VERSION "J35_6MT"

NS_ :

BS_:

BU_: PCM UNKNOWN

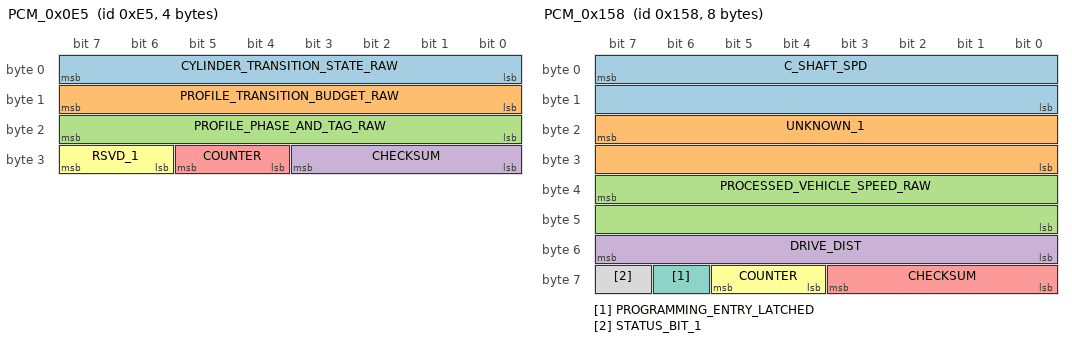
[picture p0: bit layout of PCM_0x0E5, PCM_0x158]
BO_ 229 PCM_0x0E5: 4 PCM
 SG_ CYLINDER_TRANSITION_STATE_RAW : 0|8@1+ (1,0) [0|255] ""  UNKNOWN
 SG_ PROFILE_TRANSITION_BUDGET_RAW : 8|8@1+ (1,0) [0|255] ""  UNKNOWN
 SG_ PROFILE_PHASE_AND_TAG_RAW : 16|8@1+ (1,0) [0|255] ""  UNKNOWN
 SG_ CHECKSUM : 24|4@1+ (1,0) [0|15] ""  UNKNOWN
 SG_ COUNTER : 28|2@1+ (1,0) [0|3] ""  UNKNOWN
 SG_ RSVD_1 : 30|2@1+ (1,0) [0|3] ""  UNKNOWN

BO_ 316 PCM_0x13C: 8 PCM
 SG_ TORQUE_ESTIMATE : 7|16@0- (1,0) [-32768|32767] "raw"  UNKNOWN
 SG_ TORQUE_TARGET : 23|16@0- (1,0) [-32768|32767] "raw"  UNKNOWN
 SG_ APP_SENSOR : 32|8@1+ (0.39215686274509803,0) [0|100] "%"  UNKNOWN
 SG_ TORQUE_STATE : 40|2@1+ (1,0) [0|3] ""  UNKNOWN
 SG_ RSVD_1 : 42|2@1+ (1,0) [0|3] ""  UNKNOWN
 SG_ RSVD_2 : 44|1@1+ (1,0) [0|1] ""  UNKNOWN
 SG_ FRAME_1AA_WINDOW_LATCH : 45|1@1+ (1,0) [0|1] ""  UNKNOWN
 SG_ START_PHASE_LATCH : 46|1@1+ (1,0) [0|1] ""  UNKNOWN
 SG_ DTC_STATUS_7_LATCH : 47|1@1+ (1,0) [0|1] ""  UNKNOWN
 SG_ RSVD_3 : 48|2@1+ (1,0) [0|3] ""  UNKNOWN
 SG_ CLUTCH_ENGAGEMENT_INFORMATION_CRUISE_CONTROL : 50|1@1+ (1,0) [0|1] ""  UNKNOWN
 SG_ CONTROL_GUARD_RAW : 51|1@1+ (1,0) [0|1] ""  UNKNOWN
 SG_ RSVD_4 : 52|4@1+ (1,0) [0|15] ""  UNKNOWN
 SG_ CHECKSUM : 56|4@1+ (1,0) [0|15] ""  UNKNOWN
 SG_ COUNTER : 60|2@1+ (1,0) [0|3] ""  UNKNOWN
 SG_ RSVD_5 : 62|1@1+ (1,0) [0|1] ""  UNKNOWN
 SG_ FRAME_1AA_INVALID_OR_FALLBACK_STATE_TBD : 63|1@1+ (1,0) [0|1] ""  UNKNOWN
VAL_ 316 CLUTCH_ENGAGEMENT_INFORMATION_CRUISE_CONTROL 0 "ON" 1 "OFF" ;
VAL_ 316 TORQUE_STATE 0 "NORMAL" 1 "VSA_CONTROL_CANDIDATE" 2 "FUEL_CUT" 3 "UNKNOWN" ;

BO_ 344 PCM_0x158: 8 PCM
 SG_ C_SHAFT_SPD : 7|16@0+ (0.01,0) [0|655.35] ""  UNKNOWN
 SG_ UNKNOWN_1 : 23|16@0+ (1,0) [0|65535] ""  UNKNOWN
 SG_ PROCESSED_VEHICLE_SPEED_RAW : 39|16@0+ (0.01,0) [0|655.35] ""  UNKNOWN
 SG_ DRIVE_DIST : 48|8@1+ (1,0) [0|255] "raw"  UNKNOWN
 SG_ CHECKSUM : 56|4@1+ (1,0) [0|15] ""  UNKNOWN
 SG_ COUNTER : 60|2@1+ (1,0) [0|3] ""  UNKNOWN
 SG_ PROGRAMMING_ENTRY_LATCHED : 62|1@1+ (1,0) [0|1] ""  UNKNOWN
 SG_ STATUS_BIT_1 : 63|1@1+ (1,0) [0|1] ""  UNKNOWN

BO_ 380 PCM_0x17C: 8 PCM
 SG_ APP_SENSOR : 0|8@1+ (0.39215686274509803,0) [0|100] "%"  UNKNOWN
 SG_ THROTTLE_ABOVE_IDLE_CODE : 8|8@1+ (0.4,0) [0|102] "deg"  UNKNOWN
 SG_ ENGINE_SPEED : 23|16@0+ (1,0) [0|65535] "rpm"  UNKNOWN
 SG_ BRAKE_SWITCH : 32|1@1+ (1,0) [0|1] ""  UNKNOWN
 SG_ CRUISE_CANCEL_EVENT : 33|1@1+ (1,0) [0|1] ""  UNKNOWN
 SG_ CRUISE_FAULT_SPEED_INHIBIT : 34|1@1+ (1,0) [0|1] ""  UNKNOWN
 SG_ CRUISE_ENGAGED : 35|1@1+ (1,0) [0|1] ""  UNKNOWN
 SG_ MIL : 36|1@1+ (1,0) [0|1] ""  UNKNOWN
 SG_ MIL_STATUS : 37|1@1+ (1,0) [0|1] ""  UNKNOWN
 SG_ CRUISE_INDICATOR : 38|1@1+ (1,0) [0|1] ""  UNKNOWN
 SG_ GAS_PEDAL_PRESSED : 39|1@1+ (1,0) [0|1] ""  UNKNOWN
 SG_ RSVD_1 : 40|2@1+ (1,0) [0|3] ""  UNKNOWN
 SG_ ACCEL_PEDAL_FAULT : 42|1@1+ (1,0) [0|1] ""  UNKNOWN
 SG_ RSVD_2 : 43|5@1+ (1,0) [0|31] ""  UNKNOWN
 SG_ RSVD_3 : 48|5@1+ (1,0) [0|31] ""  UNKNOWN
 SG_ CRUISE_BRAKE_SW_IDLE_STOP_SW : 53|1@1+ (1,0) [0|1] ""  UNKNOWN
 SG_ CRUISE_TRANS_REQUEST_WIRE : 54|2@1+ (1,0) [0|3] ""  UNKNOWN
 SG_ CHECKSUM : 56|4@1+ (1,0) [0|15] ""  UNKNOWN
 SG_ COUNTER : 60|2@1+ (1,0) [0|3] ""  UNKNOWN
 SG_ RSVD_4 : 62|1@1+ (1,0) [0|1] ""  UNKNOWN
 SG_ DTC_GROUP_WARNING_REQUESTED : 63|1@1+ (1,0) [0|1] ""  UNKNOWN
VAL_ 380 CRUISE_BRAKE_SW_IDLE_STOP_SW 0 "CLOSE" 1 "OPEN" ;
VAL_ 380 CRUISE_INDICATOR 0 "OFF" 1 "ON" ;
VAL_ 380 MIL_STATUS 0 "OFF" 1 "ON" ;
VAL_ 380 MIL 0 "OFF" 1 "ON" ;
VAL_ 380 BRAKE_SWITCH 0 "OFF" 1 "ON" ;

BO_ 392 PCM_0x188: 6 PCM
 SG_ SHIFT_CONTROL_CODE_A_RAW : 0|4@1+ (1,0) [0|15] ""  UNKNOWN
 SG_ TRANSMISSION_LATCH_RAW : 4|1@1+ (1,0) [0|1] ""  UNKNOWN
 SG_ CONDITIONED_GEAR_CODE_RAW : 5|3@1+ (1,0) [0|7] ""  UNKNOWN
 SG_ SHIFT_CONTROL_CODE_B_RAW : 8|3@1+ (1,0) [0|7] ""  UNKNOWN
 SG_ LED_C : 11|1@1+ (1,0) [0|1] ""  UNKNOWN
 SG_ LED_B : 12|1@1+ (1,0) [0|1] ""  UNKNOWN
 SG_ LED_A : 13|1@1+ (1,0) [0|1] ""  UNKNOWN
 SG_ SIGNED_CODE_SPILL_D1_RAW : 14|2@1+ (1,0) [0|3] ""  UNKNOWN
 SG_ SELECTOR_INDICATOR_RAW : 16|1@1+ (1,0) [0|1] ""  UNKNOWN
 SG_ TRANSMISSION_STATE_RAW : 17|1@1+ (1,0) [0|1] ""  UNKNOWN
 SG_ TRANSMISSION_QUALIFICATION_RAW : 18|1@1+ (1,0) [0|1] ""  UNKNOWN
 SG_ MANUAL_MODE_INDICATOR : 19|1@1+ (1,0) [0|1] ""  UNKNOWN
 SG_ INDICATOR_FAULT_RAW : 20|1@1+ (1,0) [0|1] ""  UNKNOWN
 SG_ TRANSMISSION_DIAGNOSTIC_LATCH_RAW : 21|1@1+ (1,0) [0|1] ""  UNKNOWN
 SG_ COMMUNICATION_STATUS_RAW : 22|1@1+ (1,0) [0|1] ""  UNKNOWN
 SG_ SHIFT_INDICATOR_CONTROL_RAW : 23|1@1+ (1,0) [0|1] ""  UNKNOWN
 SG_ A_T_P_SWITCH : 24|1@1+ (1,0) [0|1] ""  UNKNOWN
 SG_ A_T_R_SWITCH : 25|1@1+ (1,0) [0|1] ""  UNKNOWN
 SG_ A_T_N_SWITCH : 26|1@1+ (1,0) [0|1] ""  UNKNOWN
 SG_ A_T_D_SWITCH : 27|1@1+ (1,0) [0|1] ""  UNKNOWN
 SG_ RSVD_1 : 28|1@1+ (1,0) [0|1] ""  UNKNOWN
 SG_ A_T_D3_SWITCH : 29|1@1+ (1,0) [0|1] ""  UNKNOWN
 SG_ A_T_2_SWITCH_OR_A_T_L_SWITCH : 30|1@1+ (1,0) [0|1] ""  UNKNOWN
 SG_ A_T_1_SWITCH : 31|1@1+ (1,0) [0|1] ""  UNKNOWN
 SG_ SHIFT_POSITION_DISPLAY_CODE_RAW : 32|4@1+ (1,0) [0|15] ""  UNKNOWN
 SG_ A_T_S_SWITCH : 36|1@1+ (1,0) [0|1] ""  UNKNOWN
 SG_ SERVICE_RESET_ACK_RAW : 37|1@1+ (1,0) [0|1] ""  UNKNOWN
 SG_ SERVICE_DUE_RAW : 38|1@1+ (1,0) [0|1] ""  UNKNOWN
 SG_ SIGNED_CODE_SPILL_D4_RAW : 39|1@1+ (1,0) [0|1] ""  UNKNOWN
 SG_ CHECKSUM : 40|4@1+ (1,0) [0|15] ""  UNKNOWN
 SG_ COUNTER : 44|2@1+ (1,0) [0|3] ""  UNKNOWN
 SG_ QUALIFIED_TRANSMISSION_STATUS_RAW : 46|1@1+ (1,0) [0|1] ""  UNKNOWN
 SG_ RSVD_2 : 47|1@1+ (1,0) [0|1] ""  UNKNOWN
VAL_ 392 A_T_S_SWITCH 0 "OFF" 1 "ON" ;
VAL_ 392 A_T_1_SWITCH 0 "OFF" 1 "ON" ;
VAL_ 392 A_T_D3_SWITCH 0 "OFF" 1 "ON" ;
VAL_ 392 A_T_D_SWITCH 0 "OFF" 1 "ON" ;
VAL_ 392 A_T_N_SWITCH 0 "OFF" 1 "ON" ;
VAL_ 392 A_T_R_SWITCH 0 "OFF" 1 "ON" ;
VAL_ 392 A_T_P_SWITCH 0 "OFF" 1 "ON" ;
VAL_ 392 MANUAL_MODE_INDICATOR 0 "OFF" 1 "ON" ;
VAL_ 392 LED_A 0 "OFF" 1 "ON" ;
VAL_ 392 LED_B 0 "OFF" 1 "ON" ;
VAL_ 392 LED_C 0 "OFF" 1 "ON" ;

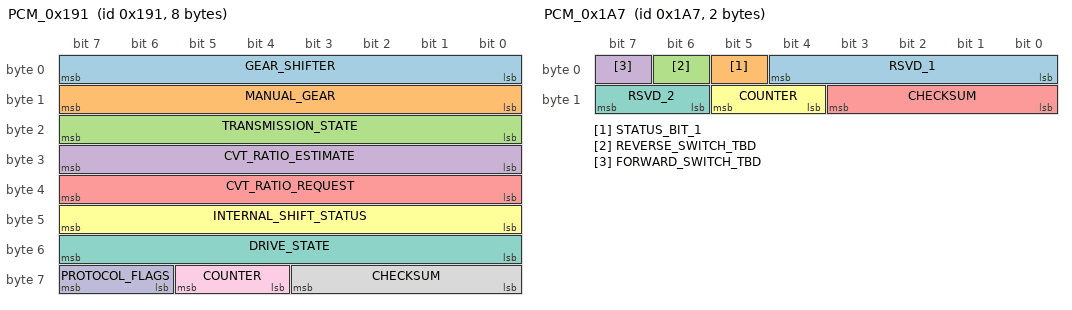
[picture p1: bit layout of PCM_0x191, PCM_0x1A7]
BO_ 401 PCM_0x191: 8 PCM
 SG_ GEAR_SHIFTER : 0|8@1+ (1,0) [0|255] ""  UNKNOWN
 SG_ MANUAL_GEAR : 8|8@1+ (1,0) [0|255] ""  UNKNOWN
 SG_ TRANSMISSION_STATE : 16|8@1+ (1,0) [0|255] ""  UNKNOWN
 SG_ CVT_RATIO_ESTIMATE : 24|8@1+ (1,0) [0|255] ""  UNKNOWN
 SG_ CVT_RATIO_REQUEST : 32|8@1+ (1,0) [0|255] ""  UNKNOWN
 SG_ INTERNAL_SHIFT_STATUS : 40|8@1+ (1,0) [0|255] ""  UNKNOWN
 SG_ DRIVE_STATE : 48|8@1+ (1,0) [0|255] ""  UNKNOWN
 SG_ CHECKSUM : 56|4@1+ (1,0) [0|15] ""  UNKNOWN
 SG_ COUNTER : 60|2@1+ (1,0) [0|3] ""  UNKNOWN
 SG_ PROTOCOL_FLAGS : 62|2@1+ (1,0) [0|3] ""  UNKNOWN

BO_ 423 PCM_0x1A7: 2 PCM
 SG_ RSVD_1 : 0|5@1+ (1,0) [0|31] ""  UNKNOWN
 SG_ STATUS_BIT_1 : 5|1@1+ (1,0) [0|1] ""  UNKNOWN
 SG_ REVERSE_SWITCH_TBD : 6|1@1+ (1,0) [0|1] ""  UNKNOWN
 SG_ FORWARD_SWITCH_TBD : 7|1@1+ (1,0) [0|1] ""  UNKNOWN
 SG_ CHECKSUM : 8|4@1+ (1,0) [0|15] ""  UNKNOWN
 SG_ COUNTER : 12|2@1+ (1,0) [0|3] ""  UNKNOWN
 SG_ RSVD_2 : 14|2@1+ (1,0) [0|3] ""  UNKNOWN

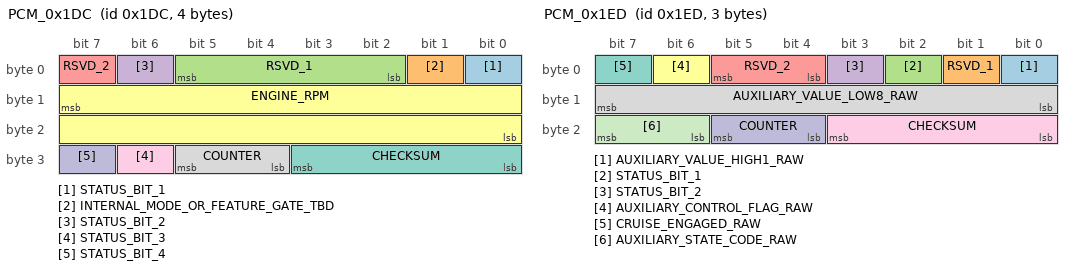
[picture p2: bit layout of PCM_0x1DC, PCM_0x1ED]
BO_ 476 PCM_0x1DC: 4 PCM
 SG_ STATUS_BIT_1 : 0|1@1+ (1,0) [0|1] ""  UNKNOWN
 SG_ INTERNAL_MODE_OR_FEATURE_GATE_TBD : 1|1@1+ (1,0) [0|1] ""  UNKNOWN
 SG_ RSVD_1 : 2|4@1+ (1,0) [0|15] ""  UNKNOWN
 SG_ STATUS_BIT_2 : 6|1@1+ (1,0) [0|1] ""  UNKNOWN
 SG_ RSVD_2 : 7|1@1+ (1,0) [0|1] ""  UNKNOWN
 SG_ ENGINE_RPM : 15|16@0+ (1,0) [0|65535] "rpm"  UNKNOWN
 SG_ CHECKSUM : 24|4@1+ (1,0) [0|15] ""  UNKNOWN
 SG_ COUNTER : 28|2@1+ (1,0) [0|3] ""  UNKNOWN
 SG_ STATUS_BIT_3 : 30|1@1+ (1,0) [0|1] ""  UNKNOWN
 SG_ STATUS_BIT_4 : 31|1@1+ (1,0) [0|1] ""  UNKNOWN

BO_ 493 PCM_0x1ED: 3 PCM
 SG_ AUXILIARY_VALUE_HIGH1_RAW : 0|1@1+ (1,0) [0|1] ""  UNKNOWN
 SG_ RSVD_1 : 1|1@1+ (1,0) [0|1] ""  UNKNOWN
 SG_ STATUS_BIT_1 : 2|1@1+ (1,0) [0|1] ""  UNKNOWN
 SG_ STATUS_BIT_2 : 3|1@1+ (1,0) [0|1] ""  UNKNOWN
 SG_ RSVD_2 : 4|2@1+ (1,0) [0|3] ""  UNKNOWN
 SG_ AUXILIARY_CONTROL_FLAG_RAW : 6|1@1+ (1,0) [0|1] ""  UNKNOWN
 SG_ CRUISE_ENGAGED_RAW : 7|1@1+ (1,0) [0|1] ""  UNKNOWN
 SG_ AUXILIARY_VALUE_LOW8_RAW : 8|8@1+ (1,0) [0|255] ""  UNKNOWN
 SG_ CHECKSUM : 16|4@1+ (1,0) [0|15] ""  UNKNOWN
 SG_ COUNTER : 20|2@1+ (1,0) [0|3] ""  UNKNOWN
 SG_ AUXILIARY_STATE_CODE_RAW : 22|2@1+ (1,0) [0|3] ""  UNKNOWN

BO_ 800 BCM_0x320: 8 PCM
 SG_ RSVD_1 : 0|6@1+ (1,0) [0|63] ""  UNKNOWN
 SG_ ENGINE_STATE_CODE_TBD : 6|2@1+ (1,0) [0|3] ""  UNKNOWN
 SG_ STATUS_BIT_1 : 8|1@1+ (1,0) [0|1] ""  UNKNOWN
 SG_ STATUS_BIT_2 : 9|1@1+ (1,0) [0|1] ""  UNKNOWN
 SG_ RSVD_2 : 10|4@1+ (1,0) [0|15] ""  UNKNOWN
 SG_ STATUS_BIT_3 : 14|1@1+ (1,0) [0|1] ""  UNKNOWN
 SG_ RSVD_3 : 15|1@1+ (1,0) [0|1] ""  UNKNOWN
 SG_ UNKNOWN_1 : 16|3@1+ (1,0) [0|7] ""  UNKNOWN
 SG_ SIGNED_CAP_OUT_OF_DOMAIN_HIGH_BITS_B2_TBD : 19|3@1+ (1,0) [0|7] ""  UNKNOWN
 SG_ STATUS_BIT_4 : 22|1@1+ (1,0) [0|1] ""  UNKNOWN
 SG_ SIGNED_CAP_OUT_OF_DOMAIN_SIGN_BIT_B2_TBD : 23|1@1+ (1,0) [0|1] ""  UNKNOWN
 SG_ RSVD_4 : 24|8@1+ (1,0) [0|255] ""  UNKNOWN
 SG_ RSVD_5 : 32|7@1+ (1,0) [0|127] ""  UNKNOWN
 SG_ STATUS_BIT_5 : 39|1@1+ (1,0) [0|1] ""  UNKNOWN
 SG_ UNKNOWN_2 : 40|3@1+ (1,0) [0|7] ""  UNKNOWN
 SG_ UNKNOWN_3 : 43|3@1+ (1,0) [0|7] ""  UNKNOWN
 SG_ SIGNED_CAP_OUT_OF_DOMAIN_HIGH_BITS_B5_TBD : 46|2@1+ (1,0) [0|3] ""  UNKNOWN
 SG_ STATUS_BIT_6 : 48|1@1+ (1,0) [0|1] ""  UNKNOWN
 SG_ RSVD_6 : 49|2@1+ (1,0) [0|3] ""  UNKNOWN
 SG_ STATUS_BIT_7 : 51|1@1+ (1,0) [0|1] ""  UNKNOWN
 SG_ RSVD_7 : 52|4@1+ (1,0) [0|15] ""  UNKNOWN
 SG_ CHECKSUM : 56|4@1+ (1,0) [0|15] ""  UNKNOWN
 SG_ COUNTER : 60|2@1+ (1,0) [0|3] ""  UNKNOWN
 SG_ STATUS_BIT_8 : 62|1@1+ (1,0) [0|1] ""  UNKNOWN
 SG_ STATUS_BIT_9 : 63|1@1+ (1,0) [0|1] ""  UNKNOWN

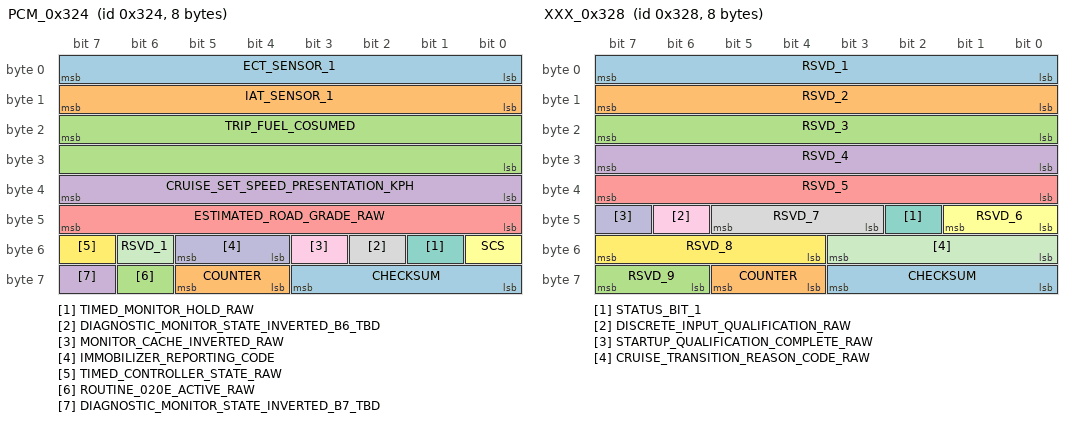
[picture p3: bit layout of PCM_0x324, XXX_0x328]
BO_ 804 PCM_0x324: 8 PCM
 SG_ ECT_SENSOR_1 : 0|8@1+ (1,-40) [-40|215] "degC"  UNKNOWN
 SG_ IAT_SENSOR_1 : 8|8@1+ (1,-40) [-40|215] "degC"  UNKNOWN
 SG_ TRIP_FUEL_COSUMED : 23|16@0+ (1,0) [0|65535] ""  UNKNOWN
 SG_ CRUISE_SET_SPEED_PRESENTATION_KPH : 32|8@1+ (1,0) [0|255] "raw"  UNKNOWN
 SG_ ESTIMATED_ROAD_GRADE_RAW : 40|8@1- (0.125,0) [-16|15.875] ""  UNKNOWN
 SG_ SCS : 48|1@1+ (1,0) [0|1] ""  UNKNOWN
 SG_ TIMED_MONITOR_HOLD_RAW : 49|1@1+ (1,0) [0|1] ""  UNKNOWN
 SG_ DIAGNOSTIC_MONITOR_STATE_INVERTED_B6_TBD : 50|1@1+ (1,0) [0|1] ""  UNKNOWN
 SG_ MONITOR_CACHE_INVERTED_RAW : 51|1@1+ (1,0) [0|1] ""  UNKNOWN
 SG_ IMMOBILIZER_REPORTING_CODE : 52|2@1+ (1,0) [0|3] ""  UNKNOWN
 SG_ RSVD_1 : 54|1@1+ (1,0) [0|1] ""  UNKNOWN
 SG_ TIMED_CONTROLLER_STATE_RAW : 55|1@1+ (1,0) [0|1] ""  UNKNOWN
 SG_ CHECKSUM : 56|4@1+ (1,0) [0|15] ""  UNKNOWN
 SG_ COUNTER : 60|2@1+ (1,0) [0|3] ""  UNKNOWN
 SG_ ROUTINE_020E_ACTIVE_RAW : 62|1@1+ (1,0) [0|1] ""  UNKNOWN
 SG_ DIAGNOSTIC_MONITOR_STATE_INVERTED_B7_TBD : 63|1@1+ (1,0) [0|1] ""  UNKNOWN
VAL_ 804 IMMOBILIZER_REPORTING_CODE 0 "COMPLETE_ACCEPTED" 1 "INCOMPLETE" 2 "COMPLETE_NOT_ACCEPTED" ;
VAL_ 804 SCS 0 "OPEN" 1 "SHORT" ;
VAL_ 804 IAT_SENSOR_1 255 "INVALID" ;
VAL_ 804 ECT_SENSOR_1 255 "INVALID" ;

BO_ 808 XXX_0x328: 8 PCM
 SG_ RSVD_1 : 0|8@1+ (1,0) [0|255] ""  UNKNOWN
 SG_ RSVD_2 : 8|8@1+ (1,0) [0|255] ""  UNKNOWN
 SG_ RSVD_3 : 16|8@1+ (1,0) [0|255] ""  UNKNOWN
 SG_ RSVD_4 : 24|8@1+ (1,0) [0|255] ""  UNKNOWN
 SG_ RSVD_5 : 32|8@1+ (1,0) [0|255] ""  UNKNOWN
 SG_ RSVD_6 : 40|2@1+ (1,0) [0|3] ""  UNKNOWN
 SG_ STATUS_BIT_1 : 42|1@1+ (1,0) [0|1] ""  UNKNOWN
 SG_ RSVD_7 : 43|3@1+ (1,0) [0|7] ""  UNKNOWN
 SG_ DISCRETE_INPUT_QUALIFICATION_RAW : 46|1@1+ (1,0) [0|1] ""  UNKNOWN
 SG_ STARTUP_QUALIFICATION_COMPLETE_RAW : 47|1@1+ (1,0) [0|1] ""  UNKNOWN
 SG_ CRUISE_TRANSITION_REASON_CODE_RAW : 48|4@1+ (1,0) [0|15] ""  UNKNOWN
 SG_ RSVD_8 : 52|4@1+ (1,0) [0|15] ""  UNKNOWN
 SG_ CHECKSUM : 56|4@1+ (1,0) [0|15] ""  UNKNOWN
 SG_ COUNTER : 60|2@1+ (1,0) [0|3] ""  UNKNOWN
 SG_ RSVD_9 : 62|2@1+ (1,0) [0|3] ""  UNKNOWN

BO_ 892 PCM_0x37C: 8 PCM
 SG_ UNKNOWN_1 : 0|8@1+ (1,0) [0|255] ""  UNKNOWN
 SG_ UNKNOWN_2 : 8|8@1+ (1,0) [0|255] ""  UNKNOWN
 SG_ UNKNOWN_3 : 16|8@1+ (1,0) [0|255] ""  UNKNOWN
 SG_ UNKNOWN_4 : 24|8@1+ (1,0) [0|255] ""  UNKNOWN
 SG_ RSVD_1 : 32|8@1+ (1,0) [0|255] ""  UNKNOWN
 SG_ UNKNOWN_5 : 40|7@1+ (1,0) [0|127] ""  UNKNOWN
 SG_ STATUS_BIT_1 : 47|1@1+ (1,0) [0|1] ""  UNKNOWN
 SG_ STATUS_BIT_2 : 48|1@1+ (1,0) [0|1] ""  UNKNOWN
 SG_ STATUS_BIT_3 : 49|1@1+ (1,0) [0|1] ""  UNKNOWN
 SG_ STATUS_BIT_4 : 50|1@1+ (1,0) [0|1] ""  UNKNOWN
 SG_ STATUS_BIT_5 : 51|1@1+ (1,0) [0|1] ""  UNKNOWN
 SG_ STATUS_BIT_6 : 52|1@1+ (1,0) [0|1] ""  UNKNOWN
 SG_ STATUS_BIT_7 : 53|1@1+ (1,0) [0|1] ""  UNKNOWN
 SG_ STATUS_BIT_8 : 54|1@1+ (1,0) [0|1] ""  UNKNOWN
 SG_ STATUS_BIT_9 : 55|1@1+ (1,0) [0|1] ""  UNKNOWN
 SG_ CHECKSUM : 56|4@1+ (1,0) [0|15] ""  UNKNOWN
 SG_ COUNTER : 60|2@1+ (1,0) [0|3] ""  UNKNOWN
 SG_ RSVD_2 : 62|1@1+ (1,0) [0|1] ""  UNKNOWN
 SG_ STATUS_BIT_10 : 63|1@1+ (1,0) [0|1] ""  UNKNOWN

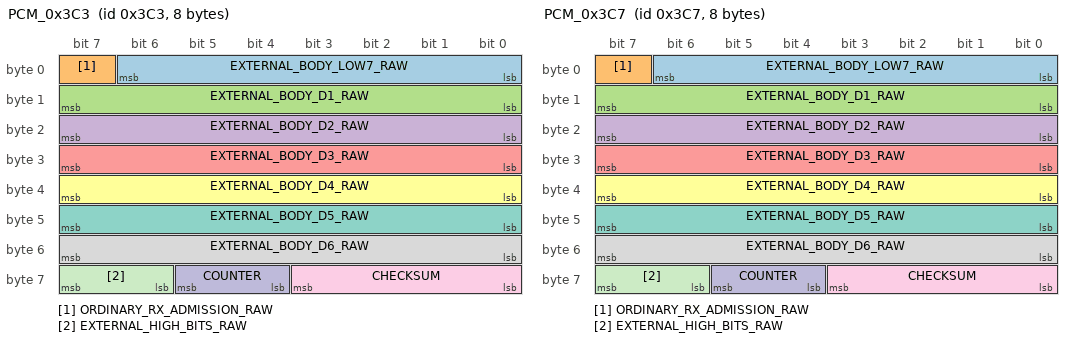
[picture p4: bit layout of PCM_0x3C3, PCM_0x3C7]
BO_ 963 PCM_0x3C3: 8 PCM
 SG_ EXTERNAL_BODY_LOW7_RAW : 0|7@1+ (1,0) [0|0] ""  UNKNOWN
 SG_ ORDINARY_RX_ADMISSION_RAW : 7|1@1+ (1,0) [0|0] ""  UNKNOWN
 SG_ EXTERNAL_BODY_D1_RAW : 8|8@1+ (1,0) [0|0] ""  UNKNOWN
 SG_ EXTERNAL_BODY_D2_RAW : 16|8@1+ (1,0) [0|0] ""  UNKNOWN
 SG_ EXTERNAL_BODY_D3_RAW : 24|8@1+ (1,0) [0|0] ""  UNKNOWN
 SG_ EXTERNAL_BODY_D4_RAW : 32|8@1+ (1,0) [0|0] ""  UNKNOWN
 SG_ EXTERNAL_BODY_D5_RAW : 40|8@1+ (1,0) [0|0] ""  UNKNOWN
 SG_ EXTERNAL_BODY_D6_RAW : 48|8@1+ (1,0) [0|0] ""  UNKNOWN
 SG_ CHECKSUM : 56|4@1+ (1,0) [0|0] ""  UNKNOWN
 SG_ COUNTER : 60|2@1+ (1,0) [0|0] ""  UNKNOWN
 SG_ EXTERNAL_HIGH_BITS_RAW : 62|2@1+ (1,0) [0|0] ""  UNKNOWN

BO_ 967 PCM_0x3C7: 8 PCM
 SG_ EXTERNAL_BODY_LOW7_RAW : 0|7@1+ (1,0) [0|0] ""  UNKNOWN
 SG_ ORDINARY_RX_ADMISSION_RAW : 7|1@1+ (1,0) [0|0] ""  UNKNOWN
 SG_ EXTERNAL_BODY_D1_RAW : 8|8@1+ (1,0) [0|0] ""  UNKNOWN
 SG_ EXTERNAL_BODY_D2_RAW : 16|8@1+ (1,0) [0|0] ""  UNKNOWN
 SG_ EXTERNAL_BODY_D3_RAW : 24|8@1+ (1,0) [0|0] ""  UNKNOWN
 SG_ EXTERNAL_BODY_D4_RAW : 32|8@1+ (1,0) [0|0] ""  UNKNOWN
 SG_ EXTERNAL_BODY_D5_RAW : 40|8@1+ (1,0) [0|0] ""  UNKNOWN
 SG_ EXTERNAL_BODY_D6_RAW : 48|8@1+ (1,0) [0|0] ""  UNKNOWN
 SG_ CHECKSUM : 56|4@1+ (1,0) [0|0] ""  UNKNOWN
 SG_ COUNTER : 60|2@1+ (1,0) [0|0] ""  UNKNOWN
 SG_ EXTERNAL_HIGH_BITS_RAW : 62|2@1+ (1,0) [0|0] ""  UNKNOWN

BO_ 983 PCM_0x3D7: 8 PCM
 SG_ MULTIPLEX_HEADER : 0|8@1+ (1,0) [0|255] ""  UNKNOWN
 SG_ RETAINED_BANK_A_CODE_WORD_0_PAGE_0 m0 : 15|16@0+ (1,0) [0|65535] ""  UNKNOWN
 SG_ RETAINED_BANK_A_CODE_WORD_0_PAGE_1 m1 : 15|16@0+ (1,0) [0|65535] ""  UNKNOWN
 SG_ RETAINED_BANK_A_CODE_WORD_1_PAGE_0 m0 : 31|16@0+ (1,0) [0|65535] ""  UNKNOWN
 SG_ RETAINED_BANK_A_CODE_WORD_1_PAGE_1 m1 : 31|16@0+ (1,0) [0|65535] ""  UNKNOWN
 SG_ RETAINED_BANK_A_CODE_WORD_2_PAGE_0 m0 : 47|16@0+ (1,0) [0|65535] ""  UNKNOWN
 SG_ RETAINED_BANK_A_CODE_WORD_2_PAGE_1 m1 : 47|16@0+ (1,0) [0|65535] ""  UNKNOWN
 SG_ CHECKSUM : 56|4@1+ (1,0) [0|15] ""  UNKNOWN
 SG_ COUNTER : 60|2@1+ (1,0) [0|3] ""  UNKNOWN
 SG_ PAGE_INDEX M : 62|1@1+ (1,0) [0|1] ""  UNKNOWN
 SG_ PROTOCOL_BIT7 : 63|1@1+ (1,0) [0|1] ""  UNKNOWN
VAL_ 983 PAGE_INDEX 0 "SLOTS0_TO2" 1 "SLOTS3_TO5" ;
SG_MUL_VAL_ 983 RETAINED_BANK_A_CODE_WORD_0_PAGE_0 PAGE_INDEX 0-0;
SG_MUL_VAL_ 983 RETAINED_BANK_A_CODE_WORD_0_PAGE_1 PAGE_INDEX 1-1;
SG_MUL_VAL_ 983 RETAINED_BANK_A_CODE_WORD_1_PAGE_0 PAGE_INDEX 0-0;
SG_MUL_VAL_ 983 RETAINED_BANK_A_CODE_WORD_1_PAGE_1 PAGE_INDEX 1-1;
SG_MUL_VAL_ 983 RETAINED_BANK_A_CODE_WORD_2_PAGE_0 PAGE_INDEX 0-0;
SG_MUL_VAL_ 983 RETAINED_BANK_A_CODE_WORD_2_PAGE_1 PAGE_INDEX 1-1;

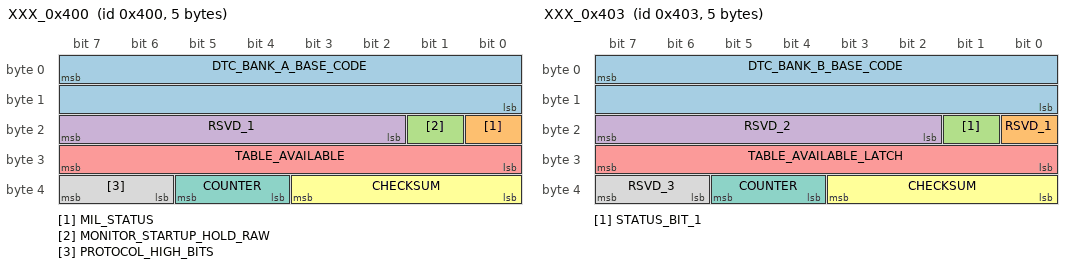
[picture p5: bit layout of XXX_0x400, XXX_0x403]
BO_ 1024 XXX_0x400: 5 PCM
 SG_ DTC_BANK_A_BASE_CODE : 7|16@0+ (1,0) [0|65535] ""  UNKNOWN
 SG_ MIL_STATUS : 16|1@1+ (1,0) [0|1] ""  UNKNOWN
 SG_ MONITOR_STARTUP_HOLD_RAW : 17|1@1+ (1,0) [0|1] ""  UNKNOWN
 SG_ RSVD_1 : 18|6@1+ (1,0) [0|63] ""  UNKNOWN
 SG_ TABLE_AVAILABLE : 24|8@1+ (1,0) [0|255] ""  UNKNOWN
 SG_ CHECKSUM : 32|4@1+ (1,0) [0|15] ""  UNKNOWN
 SG_ COUNTER : 36|2@1+ (1,0) [0|3] ""  UNKNOWN
 SG_ PROTOCOL_HIGH_BITS : 38|2@1+ (1,0) [0|3] ""  UNKNOWN
VAL_ 1024 MIL_STATUS 0 "OFF" 1 "ON" ;

BO_ 1027 XXX_0x403: 5 PCM
 SG_ DTC_BANK_B_BASE_CODE : 7|16@0+ (1,0) [0|65535] ""  UNKNOWN
 SG_ RSVD_1 : 16|1@1+ (1,0) [0|1] ""  UNKNOWN
 SG_ STATUS_BIT_1 : 17|1@1+ (1,0) [0|1] ""  UNKNOWN
 SG_ RSVD_2 : 18|6@1+ (1,0) [0|63] ""  UNKNOWN
 SG_ TABLE_AVAILABLE_LATCH : 24|8@1+ (1,0) [0|255] ""  UNKNOWN
 SG_ CHECKSUM : 32|4@1+ (1,0) [0|15] ""  UNKNOWN
 SG_ COUNTER : 36|2@1+ (1,0) [0|3] ""  UNKNOWN
 SG_ RSVD_3 : 38|2@1+ (1,0) [0|3] ""  UNKNOWN

BO_ 1036 XXX_0x40C: 8 PCM
 SG_ MULTIPLEX_PAGE M : 0|4@1+ (1,0) [0|15] ""  UNKNOWN
 SG_ MULTIPLEX_GROUP : 4|2@1+ (1,0) [0|3] ""  UNKNOWN
 SG_ DIAGNOSTIC_EVENT_STATE : 6|2@1+ (1,0) [0|3] ""  UNKNOWN
 SG_ UNKNOWN_1 m0 : 8|8@1+ (1,0) [0|255] ""  UNKNOWN
 SG_ UNKNOWN_2 m1 : 8|8@1+ (1,0) [0|255] ""  UNKNOWN
 SG_ UNKNOWN_3 m2 : 8|8@1+ (1,0) [0|255] ""  UNKNOWN
 SG_ UNKNOWN_4 m3 : 8|8@1+ (1,0) [0|255] ""  UNKNOWN
 SG_ UNKNOWN_5 m4 : 8|8@1+ (1,0) [0|255] ""  UNKNOWN
 SG_ P05_ENGINE_SPEED m5 : 15|16@0+ (0.25,0) [0|16383.75] "rpm"  UNKNOWN
 SG_ UNKNOWN_6 m6 : 8|8@1+ (0.0196078431372549,0) [0|5] "V"  UNKNOWN
 SG_ UNKNOWN_7 m7 : 8|8@1+ (1,0) [0|255] "km/h"  UNKNOWN
 SG_ UNKNOWN_8 m8 : 15|16@0+ (0.005,0) [0|327.675] "%"  UNKNOWN
 SG_ UNKNOWN_9 m9 : 15|16@0+ (0.005,0) [0|327.675] "deg"  UNKNOWN
 SG_ UNKNOWN_10 m10 : 15|16@0+ (1,0) [0|65535] ""  UNKNOWN
 SG_ UNKNOWN_11 m11 : 8|8@1+ (1,0) [0|255] ""  UNKNOWN
 SG_ UNKNOWN_12 m12 : 8|8@1+ (1,0) [0|255] ""  UNKNOWN
 SG_ UNKNOWN_13 m13 : 8|8@1+ (1,0) [0|255] ""  UNKNOWN
 SG_ UNKNOWN_14 m14 : 15|16@0+ (0.01,0) [0|655.35] "g/s"  UNKNOWN
 SG_ UNKNOWN_15 m15 : 8|8@1+ (0.39215686274509803,0) [0|100] "%"  UNKNOWN
 SG_ UNKNOWN_16 m0 : 23|16@0+ (1,0) [0|65535] ""  UNKNOWN
 SG_ UNKNOWN_17 m1 : 16|8@1+ (1,0) [0|255] ""  UNKNOWN
 SG_ UNKNOWN_18 m2 : 16|8@1+ (1,0) [0|255] ""  UNKNOWN
 SG_ UNKNOWN_19 m3 : 16|8@1+ (1,0) [0|255] ""  UNKNOWN
 SG_ UNKNOWN_20 m4 : 16|8@1+ (1,0) [0|255] ""  UNKNOWN
 SG_ UNKNOWN_21 m6 : 16|8@1+ (1,-40) [-40|215] "degC"  UNKNOWN
 SG_ UNKNOWN_22 m7 : 16|8@1+ (0.39215686274509803,0) [0|100] "%"  UNKNOWN
 SG_ UNKNOWN_23 m11 : 16|8@1+ (1,0) [0|255] ""  UNKNOWN
 SG_ UNKNOWN_24 m12 : 16|8@1+ (1,0) [0|255] ""  UNKNOWN
 SG_ UNKNOWN_25 m13 : 16|8@1+ (1,0) [0|255] ""  UNKNOWN
 SG_ UNKNOWN_26 m15 : 16|8@1+ (1,0) [0|255] ""  UNKNOWN
 SG_ UNKNOWN_27 m1 : 24|8@1+ (1,0) [0|255] ""  UNKNOWN
 SG_ UNKNOWN_28 m2 : 24|8@1+ (1,0) [0|255] ""  UNKNOWN
 SG_ UNKNOWN_29 m3 : 24|8@1+ (1,0) [0|255] ""  UNKNOWN
 SG_ UNKNOWN_30 m4 : 24|8@1+ (1,0) [0|255] ""  UNKNOWN
 SG_ UNKNOWN_31 m5 : 24|8@1+ (0.39215686274509803,0) [0|100] "%"  UNKNOWN
 SG_ UNKNOWN_32 m6 : 24|8@1+ (0.0196078431372549,0) [0|5] "V"  UNKNOWN
 SG_ UNKNOWN_33 m7 : 24|8@1+ (0.5,-64) [-64|63.5] "deg"  UNKNOWN
 SG_ UNKNOWN_34 m8 : 24|8@1+ (0.0196078431372549,0) [0|5] "V"  UNKNOWN
 SG_ UNKNOWN_35 m9 : 24|8@1+ (1,0) [0|255] ""  UNKNOWN
 SG_ UNKNOWN_36 m10 : 31|16@0+ (1,0) [0|65535] ""  UNKNOWN
 SG_ UNKNOWN_37 m11 : 31|16@0+ (1,0) [0|65535] ""  UNKNOWN
 SG_ UNKNOWN_38 m12 : 24|8@1+ (1,0) [0|255] ""  UNKNOWN
 SG_ UNKNOWN_39 m13 : 24|8@1+ (1,0) [0|255] ""  UNKNOWN
 SG_ UNKNOWN_40 m14 : 24|8@1+ (1,0) [0|255] ""  UNKNOWN
 SG_ UNKNOWN_41 m15 : 24|8@1+ (1,0) [0|255] ""  UNKNOWN
 SG_ UNKNOWN_42 m0 : 32|8@1+ (1,0) [0|255] ""  UNKNOWN
 SG_ UNKNOWN_43 m1 : 32|8@1+ (1,0) [0|255] ""  UNKNOWN
 SG_ UNKNOWN_44 m2 : 32|8@1+ (1,0) [0|255] ""  UNKNOWN
 SG_ UNKNOWN_45 m3 : 32|8@1+ (1,0) [0|255] ""  UNKNOWN
 SG_ UNKNOWN_46 m4 : 32|8@1+ (1,0) [0|255] ""  UNKNOWN
 SG_ UNKNOWN_47 m5 : 32|8@1+ (0.39215686274509803,0) [0|100] "%"  UNKNOWN
 SG_ UNKNOWN_48 m6 : 32|8@1+ (1,0) [0|255] "kPa"  UNKNOWN
 SG_ P07_CONTROL_MODULE_VOLTAGE_DECIVOLT_RAW m7 : 32|8@1+ (0.1,0) [0|25.5] "V"  UNKNOWN
 SG_ UNKNOWN_49 m8 : 32|8@1+ (0.0196078431372549,0) [0|5] "V"  UNKNOWN
 SG_ UNKNOWN_50 m9 : 32|8@1+ (1,0) [0|255] ""  UNKNOWN
 SG_ UNKNOWN_51 m12 : 32|8@1+ (1,0) [0|255] ""  UNKNOWN
 SG_ UNKNOWN_52 m13 : 32|8@1+ (1,0) [0|255] ""  UNKNOWN
 SG_ UNKNOWN_53 m14 : 39|16@0+ (1,0) [0|65535] "s"  UNKNOWN
 SG_ UNKNOWN_54 m15 : 32|8@1+ (1,0) [0|255] ""  UNKNOWN
 SG_ UNKNOWN_55 m0 : 40|8@1+ (1,0) [0|255] ""  UNKNOWN
 SG_ UNKNOWN_56 m1 : 40|8@1+ (1,0) [0|255] ""  UNKNOWN
 SG_ UNKNOWN_57 m2 : 40|8@1+ (1,0) [0|255] ""  UNKNOWN
 SG_ UNKNOWN_58 m3 : 40|8@1+ (1,0) [0|255] ""  UNKNOWN
 SG_ UNKNOWN_59 m4 : 40|8@1+ (1,0) [0|255] ""  UNKNOWN
 SG_ UNKNOWN_60 m5 : 40|8@1+ (0.0196078431372549,0) [0|5] "V"  UNKNOWN
 SG_ UNKNOWN_61 m6 : 40|8@1+ (0.0196078431372549,0) [0|5] "V"  UNKNOWN
 SG_ UNKNOWN_62 m7 : 40|8@1+ (0.0196078431372549,0) [0|5] "V"  UNKNOWN
 SG_ UNKNOWN_63 m8 : 47|16@0+ (0.005,0) [0|327.675] "deg"  UNKNOWN
 SG_ UNKNOWN_64 m9 : 47|16@0+ (0.005,0) [0|327.675] "deg"  UNKNOWN
 SG_ UNKNOWN_65 m10 : 40|8@1+ (1,0) [0|255] ""  UNKNOWN
 SG_ UNKNOWN_66 m11 : 47|16@0+ (1,0) [0|65535] ""  UNKNOWN
 SG_ UNKNOWN_67 m12 : 47|16@0+ (1,0) [0|65535] ""  UNKNOWN
 SG_ UNKNOWN_68 m13 : 40|8@1+ (1,0) [0|255] ""  UNKNOWN
 SG_ UNKNOWN_69 m15 : 40|8@1+ (1,0) [0|255] ""  UNKNOWN
 SG_ UNKNOWN_70 m0 : 48|8@1+ (1,0) [0|255] ""  UNKNOWN
 SG_ UNKNOWN_71 m1 : 48|8@1+ (1,0) [0|255] ""  UNKNOWN
 SG_ UNKNOWN_72 m2 : 48|8@1+ (1,0) [0|255] ""  UNKNOWN
 SG_ UNKNOWN_73 m3 : 48|8@1+ (1,0) [0|255] ""  UNKNOWN
 SG_ UNKNOWN_74 m4 : 48|8@1+ (1,0) [0|255] ""  UNKNOWN
 SG_ UNKNOWN_75 m5 : 48|8@1+ (1,-40) [-40|215] "degC"  UNKNOWN
 SG_ UNKNOWN_76 m6 : 48|8@1+ (1,0) [0|255] "kPa"  UNKNOWN
 SG_ UNKNOWN_77 m7 : 48|8@1+ (0.0196078431372549,0) [0|5] "V"  UNKNOWN
 SG_ UNKNOWN_78 m10 : 48|8@1+ (1,0) [0|255] ""  UNKNOWN
 SG_ UNKNOWN_79 m13 : 48|8@1+ (1,0) [0|255] ""  UNKNOWN
 SG_ UNKNOWN_80 m14 : 48|8@1+ (0.39215686274509803,0) [0|100] "%"  UNKNOWN
 SG_ UNKNOWN_81 m15 : 48|8@1+ (1,0) [0|255] ""  UNKNOWN
 SG_ CHECKSUM : 56|4@1+ (1,0) [0|15] ""  UNKNOWN
 SG_ COUNTER : 60|2@1+ (1,0) [0|3] ""  UNKNOWN
 SG_ DIAGNOSTIC_STATUS_FLAG6 : 62|1@1+ (1,0) [0|1] ""  UNKNOWN
 SG_ DIAGNOSTIC_STATUS_FLAG7 : 63|1@1+ (1,0) [0|1] ""  UNKNOWN
SG_MUL_VAL_ 1036 UNKNOWN_1 MULTIPLEX_PAGE 0-0;
SG_MUL_VAL_ 1036 UNKNOWN_2 MULTIPLEX_PAGE 1-1;
SG_MUL_VAL_ 1036 UNKNOWN_3 MULTIPLEX_PAGE 2-2;
SG_MUL_VAL_ 1036 UNKNOWN_4 MULTIPLEX_PAGE 3-3;
SG_MUL_VAL_ 1036 UNKNOWN_5 MULTIPLEX_PAGE 4-4;
SG_MUL_VAL_ 1036 P05_ENGINE_SPEED MULTIPLEX_PAGE 5-5;
SG_MUL_VAL_ 1036 UNKNOWN_6 MULTIPLEX_PAGE 6-6;
SG_MUL_VAL_ 1036 UNKNOWN_7 MULTIPLEX_PAGE 7-7;
SG_MUL_VAL_ 1036 UNKNOWN_8 MULTIPLEX_PAGE 8-8;
SG_MUL_VAL_ 1036 UNKNOWN_9 MULTIPLEX_PAGE 9-9;
SG_MUL_VAL_ 1036 UNKNOWN_10 MULTIPLEX_PAGE 10-10;
SG_MUL_VAL_ 1036 UNKNOWN_11 MULTIPLEX_PAGE 11-11;
SG_MUL_VAL_ 1036 UNKNOWN_12 MULTIPLEX_PAGE 12-12;
SG_MUL_VAL_ 1036 UNKNOWN_13 MULTIPLEX_PAGE 13-13;
SG_MUL_VAL_ 1036 UNKNOWN_14 MULTIPLEX_PAGE 14-14;
SG_MUL_VAL_ 1036 UNKNOWN_15 MULTIPLEX_PAGE 15-15;
SG_MUL_VAL_ 1036 UNKNOWN_16 MULTIPLEX_PAGE 0-0;
SG_MUL_VAL_ 1036 UNKNOWN_17 MULTIPLEX_PAGE 1-1;
SG_MUL_VAL_ 1036 UNKNOWN_18 MULTIPLEX_PAGE 2-2;
SG_MUL_VAL_ 1036 UNKNOWN_19 MULTIPLEX_PAGE 3-3;
SG_MUL_VAL_ 1036 UNKNOWN_20 MULTIPLEX_PAGE 4-4;
SG_MUL_VAL_ 1036 UNKNOWN_21 MULTIPLEX_PAGE 6-6;
SG_MUL_VAL_ 1036 UNKNOWN_22 MULTIPLEX_PAGE 7-7;
SG_MUL_VAL_ 1036 UNKNOWN_23 MULTIPLEX_PAGE 11-11;
SG_MUL_VAL_ 1036 UNKNOWN_24 MULTIPLEX_PAGE 12-12;
SG_MUL_VAL_ 1036 UNKNOWN_25 MULTIPLEX_PAGE 13-13;
SG_MUL_VAL_ 1036 UNKNOWN_26 MULTIPLEX_PAGE 15-15;
SG_MUL_VAL_ 1036 UNKNOWN_27 MULTIPLEX_PAGE 1-1;
SG_MUL_VAL_ 1036 UNKNOWN_28 MULTIPLEX_PAGE 2-2;
SG_MUL_VAL_ 1036 UNKNOWN_29 MULTIPLEX_PAGE 3-3;
SG_MUL_VAL_ 1036 UNKNOWN_30 MULTIPLEX_PAGE 4-4;
SG_MUL_VAL_ 1036 UNKNOWN_31 MULTIPLEX_PAGE 5-5;
SG_MUL_VAL_ 1036 UNKNOWN_32 MULTIPLEX_PAGE 6-6;
SG_MUL_VAL_ 1036 UNKNOWN_33 MULTIPLEX_PAGE 7-7;
SG_MUL_VAL_ 1036 UNKNOWN_34 MULTIPLEX_PAGE 8-8;
SG_MUL_VAL_ 1036 UNKNOWN_35 MULTIPLEX_PAGE 9-9;
SG_MUL_VAL_ 1036 UNKNOWN_36 MULTIPLEX_PAGE 10-10;
SG_MUL_VAL_ 1036 UNKNOWN_37 MULTIPLEX_PAGE 11-11;
SG_MUL_VAL_ 1036 UNKNOWN_38 MULTIPLEX_PAGE 12-12;
SG_MUL_VAL_ 1036 UNKNOWN_39 MULTIPLEX_PAGE 13-13;
SG_MUL_VAL_ 1036 UNKNOWN_40 MULTIPLEX_PAGE 14-14;
SG_MUL_VAL_ 1036 UNKNOWN_41 MULTIPLEX_PAGE 15-15;
SG_MUL_VAL_ 1036 UNKNOWN_42 MULTIPLEX_PAGE 0-0;
SG_MUL_VAL_ 1036 UNKNOWN_43 MULTIPLEX_PAGE 1-1;
SG_MUL_VAL_ 1036 UNKNOWN_44 MULTIPLEX_PAGE 2-2;
SG_MUL_VAL_ 1036 UNKNOWN_45 MULTIPLEX_PAGE 3-3;
SG_MUL_VAL_ 1036 UNKNOWN_46 MULTIPLEX_PAGE 4-4;
SG_MUL_VAL_ 1036 UNKNOWN_47 MULTIPLEX_PAGE 5-5;
SG_MUL_VAL_ 1036 UNKNOWN_48 MULTIPLEX_PAGE 6-6;
SG_MUL_VAL_ 1036 P07_CONTROL_MODULE_VOLTAGE_DECIVOLT_RAW MULTIPLEX_PAGE 7-7;
SG_MUL_VAL_ 1036 UNKNOWN_49 MULTIPLEX_PAGE 8-8;
SG_MUL_VAL_ 1036 UNKNOWN_50 MULTIPLEX_PAGE 9-9;
SG_MUL_VAL_ 1036 UNKNOWN_51 MULTIPLEX_PAGE 12-12;
SG_MUL_VAL_ 1036 UNKNOWN_52 MULTIPLEX_PAGE 13-13;
SG_MUL_VAL_ 1036 UNKNOWN_53 MULTIPLEX_PAGE 14-14;
SG_MUL_VAL_ 1036 UNKNOWN_54 MULTIPLEX_PAGE 15-15;
SG_MUL_VAL_ 1036 UNKNOWN_55 MULTIPLEX_PAGE 0-0;
SG_MUL_VAL_ 1036 UNKNOWN_56 MULTIPLEX_PAGE 1-1;
SG_MUL_VAL_ 1036 UNKNOWN_57 MULTIPLEX_PAGE 2-2;
SG_MUL_VAL_ 1036 UNKNOWN_58 MULTIPLEX_PAGE 3-3;
SG_MUL_VAL_ 1036 UNKNOWN_59 MULTIPLEX_PAGE 4-4;
SG_MUL_VAL_ 1036 UNKNOWN_60 MULTIPLEX_PAGE 5-5;
SG_MUL_VAL_ 1036 UNKNOWN_61 MULTIPLEX_PAGE 6-6;
SG_MUL_VAL_ 1036 UNKNOWN_62 MULTIPLEX_PAGE 7-7;
SG_MUL_VAL_ 1036 UNKNOWN_63 MULTIPLEX_PAGE 8-8;
SG_MUL_VAL_ 1036 UNKNOWN_64 MULTIPLEX_PAGE 9-9;
SG_MUL_VAL_ 1036 UNKNOWN_65 MULTIPLEX_PAGE 10-10;
SG_MUL_VAL_ 1036 UNKNOWN_66 MULTIPLEX_PAGE 11-11;
SG_MUL_VAL_ 1036 UNKNOWN_67 MULTIPLEX_PAGE 12-12;
SG_MUL_VAL_ 1036 UNKNOWN_68 MULTIPLEX_PAGE 13-13;
SG_MUL_VAL_ 1036 UNKNOWN_69 MULTIPLEX_PAGE 15-15;
SG_MUL_VAL_ 1036 UNKNOWN_70 MULTIPLEX_PAGE 0-0;
SG_MUL_VAL_ 1036 UNKNOWN_71 MULTIPLEX_PAGE 1-1;
SG_MUL_VAL_ 1036 UNKNOWN_72 MULTIPLEX_PAGE 2-2;
SG_MUL_VAL_ 1036 UNKNOWN_73 MULTIPLEX_PAGE 3-3;
SG_MUL_VAL_ 1036 UNKNOWN_74 MULTIPLEX_PAGE 4-4;
SG_MUL_VAL_ 1036 UNKNOWN_75 MULTIPLEX_PAGE 5-5;
SG_MUL_VAL_ 1036 UNKNOWN_76 MULTIPLEX_PAGE 6-6;
SG_MUL_VAL_ 1036 UNKNOWN_77 MULTIPLEX_PAGE 7-7;
SG_MUL_VAL_ 1036 UNKNOWN_78 MULTIPLEX_PAGE 10-10;
SG_MUL_VAL_ 1036 UNKNOWN_79 MULTIPLEX_PAGE 13-13;
SG_MUL_VAL_ 1036 UNKNOWN_80 MULTIPLEX_PAGE 14-14;
SG_MUL_VAL_ 1036 UNKNOWN_81 MULTIPLEX_PAGE 15-15;

BO_ 1039 XXX_0x40F: 8 PCM
 SG_ MULTIPLEX_PAGE M : 0|4@1+ (1,0) [0|15] ""  UNKNOWN
 SG_ MULTIPLEX_GROUP : 4|2@1+ (1,0) [0|3] ""  UNKNOWN
 SG_ DIAGNOSTIC_EVENT_STATE : 6|2@1+ (1,0) [0|3] ""  UNKNOWN
 SG_ UNKNOWN_1 m0 : 8|8@1+ (1,0) [0|255] ""  UNKNOWN
 SG_ UNKNOWN_2 m1 : 8|8@1+ (1,0) [0|255] ""  UNKNOWN
 SG_ UNKNOWN_3 m2 : 8|8@1+ (1,0) [0|255] ""  UNKNOWN
 SG_ UNKNOWN_4 m3 : 8|8@1+ (1,0) [0|255] ""  UNKNOWN
 SG_ UNKNOWN_5 m4 : 8|8@1+ (1,0) [0|255] ""  UNKNOWN
 SG_ UNKNOWN_6 m5 : 15|16@0+ (1,0) [0|65535] ""  UNKNOWN
 SG_ UNKNOWN_7 m6 : 8|8@1+ (1,0) [0|255] ""  UNKNOWN
 SG_ UNKNOWN_8 m7 : 8|8@1+ (1,0) [0|255] ""  UNKNOWN
 SG_ RSVD_1 m8 : 8|8@1+ (1,0) [0|255] ""  UNKNOWN
 SG_ UNKNOWN_9 m0 : 23|16@0+ (1,0) [0|65535] ""  UNKNOWN
 SG_ UNKNOWN_10 m1 : 16|8@1+ (1,0) [0|255] ""  UNKNOWN
 SG_ UNKNOWN_11 m2 : 16|8@1+ (1,0) [0|255] ""  UNKNOWN
 SG_ UNKNOWN_12 m3 : 16|8@1+ (1,0) [0|255] ""  UNKNOWN
 SG_ UNKNOWN_13 m4 : 16|8@1+ (1,0) [0|255] ""  UNKNOWN
 SG_ UNKNOWN_14 m6 : 16|8@1+ (1,0) [0|255] ""  UNKNOWN
 SG_ UNKNOWN_15 m7 : 16|8@1+ (1,0) [0|255] ""  UNKNOWN
 SG_ RSVD_2 m8 : 16|8@1+ (1,0) [0|255] ""  UNKNOWN
 SG_ UNKNOWN_16 m1 : 24|8@1+ (1,0) [0|255] ""  UNKNOWN
 SG_ UNKNOWN_17 m2 : 24|8@1+ (1,0) [0|255] ""  UNKNOWN
 SG_ UNKNOWN_18 m3 : 24|8@1+ (1,0) [0|255] ""  UNKNOWN
 SG_ UNKNOWN_19 m4 : 31|16@0+ (1,0) [0|65535] ""  UNKNOWN
 SG_ UNKNOWN_20 m5 : 24|8@1+ (1,0) [0|255] ""  UNKNOWN
 SG_ UNKNOWN_21 m6 : 24|8@1+ (1,0) [0|255] ""  UNKNOWN
 SG_ UNKNOWN_22 m7 : 24|8@1+ (1,0) [0|255] ""  UNKNOWN
 SG_ RSVD_3 m8 : 24|8@1+ (1,0) [0|255] ""  UNKNOWN
 SG_ UNKNOWN_23 m0 : 32|8@1+ (1,0) [0|255] ""  UNKNOWN
 SG_ UNKNOWN_24 m1 : 32|8@1+ (1,0) [0|255] ""  UNKNOWN
 SG_ UNKNOWN_25 m2 : 32|8@1+ (1,0) [0|255] ""  UNKNOWN
 SG_ UNKNOWN_26 m3 : 32|8@1+ (1,0) [0|255] ""  UNKNOWN
 SG_ UNKNOWN_27 m5 : 32|8@1+ (1,0) [0|255] ""  UNKNOWN
 SG_ UNKNOWN_28 m6 : 32|8@1+ (1,0) [0|255] ""  UNKNOWN
 SG_ UNKNOWN_29 m7 : 32|8@1+ (1,0) [0|255] ""  UNKNOWN
 SG_ RSVD_4 m8 : 32|8@1+ (1,0) [0|255] ""  UNKNOWN
 SG_ UNKNOWN_30 m0 : 40|8@1+ (1,0) [0|255] ""  UNKNOWN
 SG_ UNKNOWN_31 m1 : 40|8@1+ (1,0) [0|255] ""  UNKNOWN
 SG_ UNKNOWN_32 m2 : 40|8@1+ (1,0) [0|255] ""  UNKNOWN
 SG_ UNKNOWN_33 m3 : 40|8@1+ (1,0) [0|255] ""  UNKNOWN
 SG_ UNKNOWN_34 m4 : 47|16@0+ (1,0) [0|65535] ""  UNKNOWN
 SG_ UNKNOWN_35 m5 : 40|8@1+ (1,0) [0|255] ""  UNKNOWN
 SG_ UNKNOWN_36 m6 : 40|8@1+ (1,0) [0|255] ""  UNKNOWN
 SG_ UNKNOWN_37 m7 : 40|8@1+ (1,0) [0|255] ""  UNKNOWN
 SG_ RSVD_5 m8 : 40|8@1+ (1,0) [0|255] ""  UNKNOWN
 SG_ UNKNOWN_38 m0 : 48|8@1+ (1,0) [0|255] ""  UNKNOWN
 SG_ UNKNOWN_39 m1 : 48|8@1+ (1,0) [0|255] ""  UNKNOWN
 SG_ UNKNOWN_40 m2 : 48|8@1+ (1,0) [0|255] ""  UNKNOWN
 SG_ UNKNOWN_41 m3 : 48|8@1+ (1,0) [0|255] ""  UNKNOWN
 SG_ UNKNOWN_42 m5 : 48|8@1+ (1,0) [0|255] ""  UNKNOWN
 SG_ UNKNOWN_43 m6 : 48|8@1+ (1,0) [0|255] ""  UNKNOWN
 SG_ UNKNOWN_44 m7 : 48|8@1+ (1,0) [0|255] ""  UNKNOWN
 SG_ RSVD_6 m8 : 48|8@1+ (1,0) [0|255] ""  UNKNOWN
 SG_ CHECKSUM : 56|4@1+ (1,0) [0|15] ""  UNKNOWN
 SG_ COUNTER : 60|2@1+ (1,0) [0|3] ""  UNKNOWN
 SG_ PROTOCOL_FLAGS : 62|2@1+ (1,0) [0|3] ""  UNKNOWN
SG_MUL_VAL_ 1039 UNKNOWN_1 MULTIPLEX_PAGE 0-0;
SG_MUL_VAL_ 1039 UNKNOWN_2 MULTIPLEX_PAGE 1-1;
SG_MUL_VAL_ 1039 UNKNOWN_3 MULTIPLEX_PAGE 2-2;
SG_MUL_VAL_ 1039 UNKNOWN_4 MULTIPLEX_PAGE 3-3;
SG_MUL_VAL_ 1039 UNKNOWN_5 MULTIPLEX_PAGE 4-4;
SG_MUL_VAL_ 1039 UNKNOWN_6 MULTIPLEX_PAGE 5-5;
SG_MUL_VAL_ 1039 UNKNOWN_7 MULTIPLEX_PAGE 6-6;
SG_MUL_VAL_ 1039 UNKNOWN_8 MULTIPLEX_PAGE 7-7;
SG_MUL_VAL_ 1039 RSVD_1 MULTIPLEX_PAGE 8-15;
SG_MUL_VAL_ 1039 UNKNOWN_9 MULTIPLEX_PAGE 0-0;
SG_MUL_VAL_ 1039 UNKNOWN_10 MULTIPLEX_PAGE 1-1;
SG_MUL_VAL_ 1039 UNKNOWN_11 MULTIPLEX_PAGE 2-2;
SG_MUL_VAL_ 1039 UNKNOWN_12 MULTIPLEX_PAGE 3-3;
SG_MUL_VAL_ 1039 UNKNOWN_13 MULTIPLEX_PAGE 4-4;
SG_MUL_VAL_ 1039 UNKNOWN_14 MULTIPLEX_PAGE 6-6;
SG_MUL_VAL_ 1039 UNKNOWN_15 MULTIPLEX_PAGE 7-7;
SG_MUL_VAL_ 1039 RSVD_2 MULTIPLEX_PAGE 8-15;
SG_MUL_VAL_ 1039 UNKNOWN_16 MULTIPLEX_PAGE 1-1;
SG_MUL_VAL_ 1039 UNKNOWN_17 MULTIPLEX_PAGE 2-2;
SG_MUL_VAL_ 1039 UNKNOWN_18 MULTIPLEX_PAGE 3-3;
SG_MUL_VAL_ 1039 UNKNOWN_19 MULTIPLEX_PAGE 4-4;
SG_MUL_VAL_ 1039 UNKNOWN_20 MULTIPLEX_PAGE 5-5;
SG_MUL_VAL_ 1039 UNKNOWN_21 MULTIPLEX_PAGE 6-6;
SG_MUL_VAL_ 1039 UNKNOWN_22 MULTIPLEX_PAGE 7-7;
SG_MUL_VAL_ 1039 RSVD_3 MULTIPLEX_PAGE 8-15;
SG_MUL_VAL_ 1039 UNKNOWN_23 MULTIPLEX_PAGE 0-0;
SG_MUL_VAL_ 1039 UNKNOWN_24 MULTIPLEX_PAGE 1-1;
SG_MUL_VAL_ 1039 UNKNOWN_25 MULTIPLEX_PAGE 2-2;
SG_MUL_VAL_ 1039 UNKNOWN_26 MULTIPLEX_PAGE 3-3;
SG_MUL_VAL_ 1039 UNKNOWN_27 MULTIPLEX_PAGE 5-5;
SG_MUL_VAL_ 1039 UNKNOWN_28 MULTIPLEX_PAGE 6-6;
SG_MUL_VAL_ 1039 UNKNOWN_29 MULTIPLEX_PAGE 7-7;
SG_MUL_VAL_ 1039 RSVD_4 MULTIPLEX_PAGE 8-15;
SG_MUL_VAL_ 1039 UNKNOWN_30 MULTIPLEX_PAGE 0-0;
SG_MUL_VAL_ 1039 UNKNOWN_31 MULTIPLEX_PAGE 1-1;
SG_MUL_VAL_ 1039 UNKNOWN_32 MULTIPLEX_PAGE 2-2;
SG_MUL_VAL_ 1039 UNKNOWN_33 MULTIPLEX_PAGE 3-3;
SG_MUL_VAL_ 1039 UNKNOWN_34 MULTIPLEX_PAGE 4-4;
SG_MUL_VAL_ 1039 UNKNOWN_35 MULTIPLEX_PAGE 5-5;
SG_MUL_VAL_ 1039 UNKNOWN_36 MULTIPLEX_PAGE 6-6;
SG_MUL_VAL_ 1039 UNKNOWN_37 MULTIPLEX_PAGE 7-7;
SG_MUL_VAL_ 1039 RSVD_5 MULTIPLEX_PAGE 8-15;
SG_MUL_VAL_ 1039 UNKNOWN_38 MULTIPLEX_PAGE 0-0;
SG_MUL_VAL_ 1039 UNKNOWN_39 MULTIPLEX_PAGE 1-1;
SG_MUL_VAL_ 1039 UNKNOWN_40 MULTIPLEX_PAGE 2-2;
SG_MUL_VAL_ 1039 UNKNOWN_41 MULTIPLEX_PAGE 3-3;
SG_MUL_VAL_ 1039 UNKNOWN_42 MULTIPLEX_PAGE 5-5;
SG_MUL_VAL_ 1039 UNKNOWN_43 MULTIPLEX_PAGE 6-6;
SG_MUL_VAL_ 1039 UNKNOWN_44 MULTIPLEX_PAGE 7-7;
SG_MUL_VAL_ 1039 RSVD_6 MULTIPLEX_PAGE 8-15;

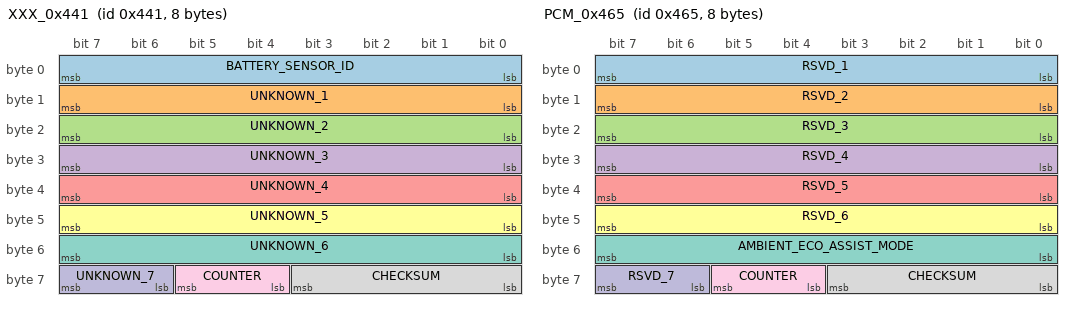
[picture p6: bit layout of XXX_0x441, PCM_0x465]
BO_ 1089 XXX_0x441: 8 PCM
 SG_ BATTERY_SENSOR_ID : 0|8@1+ (1,0) [0|255] ""  UNKNOWN
 SG_ UNKNOWN_1 : 8|8@1+ (1,0) [0|255] ""  UNKNOWN
 SG_ UNKNOWN_2 : 16|8@1+ (1,0) [0|255] ""  UNKNOWN
 SG_ UNKNOWN_3 : 24|8@1+ (1,0) [0|255] ""  UNKNOWN
 SG_ UNKNOWN_4 : 32|8@1+ (1,0) [0|255] ""  UNKNOWN
 SG_ UNKNOWN_5 : 40|8@1+ (1,0) [0|255] ""  UNKNOWN
 SG_ UNKNOWN_6 : 48|8@1+ (1,0) [0|255] ""  UNKNOWN
 SG_ CHECKSUM : 56|4@1+ (1,0) [0|15] ""  UNKNOWN
 SG_ COUNTER : 60|2@1+ (1,0) [0|3] ""  UNKNOWN
 SG_ UNKNOWN_7 : 62|2@1+ (1,0) [0|3] ""  UNKNOWN

BO_ 1108 XXX_0x454: 8 PCM
 SG_ RETAINED_MODEL_QUANTITY_RAW : 0|8@1+ (1,0) [0|255] ""  UNKNOWN
 SG_ BARO_DISPLAY_CODE_RAW : 8|8@1+ (1,0) [0|255] ""  UNKNOWN
 SG_ UNKNOWN_1 : 16|4@1+ (1,0) [0|15] ""  UNKNOWN
 SG_ BAROMETRIC_SENSOR_FAULT_AGGREGATE : 20|1@1+ (1,0) [0|1] ""  UNKNOWN
 SG_ SIGNED_STATE_BIT5_RAW : 21|1@1+ (1,0) [0|1] ""  UNKNOWN
 SG_ MODEL_HOLD_ACTIVE_RAW : 22|1@1+ (1,0) [0|1] ""  UNKNOWN
 SG_ STATUS_BIT_1 : 23|1@1+ (1,0) [0|1] ""  UNKNOWN
 SG_ SCALED_MODEL_QUANTITY_RAW : 31|16@0+ (1,0) [0|65535] ""  UNKNOWN
 SG_ RSVD_1 : 40|8@1+ (1,0) [0|255] ""  UNKNOWN
 SG_ ELECTRICAL_MONITOR_SECONDARY_RAW : 48|1@1+ (1,0) [0|1] ""  UNKNOWN
 SG_ STATUS_BIT_2 : 49|1@1+ (1,0) [0|1] ""  UNKNOWN
 SG_ STATUS_BIT_3 : 50|1@1+ (1,0) [0|1] ""  UNKNOWN
 SG_ ELECTRICAL_MONITOR_PRIMARY_RAW : 51|1@1+ (1,0) [0|1] ""  UNKNOWN
 SG_ RSVD_2 : 52|1@1+ (1,0) [0|1] ""  UNKNOWN
 SG_ RSVD_3 : 53|1@1+ (1,0) [0|1] ""  UNKNOWN
 SG_ RSVD_4 : 54|1@1+ (1,0) [0|1] ""  UNKNOWN
 SG_ MONITOR_HOLD_RAW : 55|1@1+ (1,0) [0|1] ""  UNKNOWN
 SG_ CHECKSUM : 56|4@1+ (1,0) [0|15] ""  UNKNOWN
 SG_ COUNTER : 60|2@1+ (1,0) [0|3] ""  UNKNOWN
 SG_ RSVD_5 : 62|2@1+ (1,0) [0|3] ""  UNKNOWN

BO_ 1125 PCM_0x465: 8 PCM
 SG_ RSVD_1 : 0|8@1+ (1,0) [0|255] ""  UNKNOWN
 SG_ RSVD_2 : 8|8@1+ (1,0) [0|255] ""  UNKNOWN
 SG_ RSVD_3 : 16|8@1+ (1,0) [0|255] ""  UNKNOWN
 SG_ RSVD_4 : 24|8@1+ (1,0) [0|255] ""  UNKNOWN
 SG_ RSVD_5 : 32|8@1+ (1,0) [0|255] ""  UNKNOWN
 SG_ RSVD_6 : 40|8@1+ (1,0) [0|255] ""  UNKNOWN
 SG_ AMBIENT_ECO_ASSIST_MODE : 48|8@1+ (1,0) [0|255] ""  UNKNOWN
 SG_ CHECKSUM : 56|4@1+ (1,0) [0|15] ""  UNKNOWN
 SG_ COUNTER : 60|2@1+ (1,0) [0|3] ""  UNKNOWN
 SG_ RSVD_7 : 62|2@1+ (1,0) [0|3] ""  UNKNOWN
VAL_ 1125 AMBIENT_ECO_ASSIST_MODE 1 "WHITE" 2 "LIGHT_GREEN" 3 "GREEN" ;
